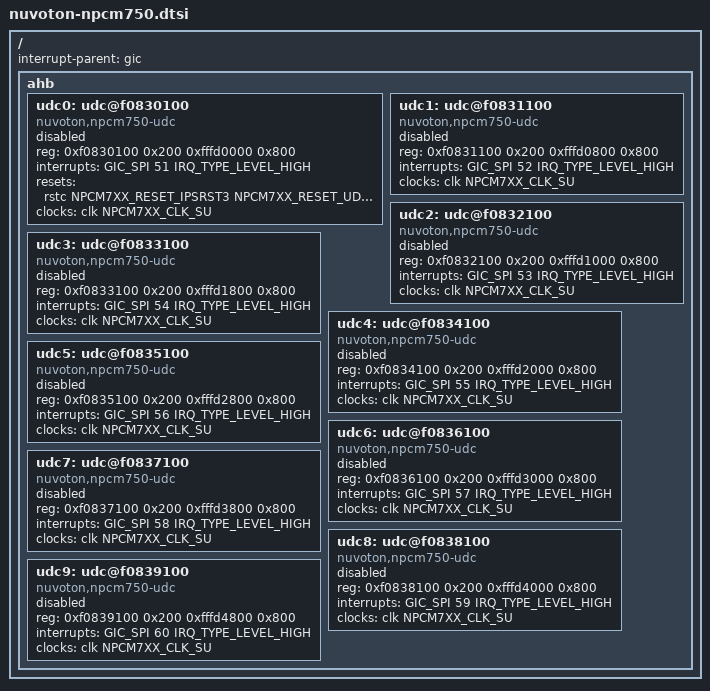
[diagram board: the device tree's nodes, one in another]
// SPDX-License-Identifier: GPL-2.0
// Copyright (c) 2018 Nuvoton Technology tomer.maimon@nuvoton.com
// Copyright 2018 Google, Inc.

#include "nuvoton-common-npcm7xx.dtsi"

/ {
	#address-cells = <1>;
	#size-cells = <1>;
	interrupt-parent = <&gic>;

	ahb {
		udc0:udc@f0830100 {
			compatible = "nuvoton,npcm750-udc";
			reg = <0xf0830100 0x200
			       0xfffd0000 0x800>;
			interrupts = <GIC_SPI 51 IRQ_TYPE_LEVEL_HIGH>;
			resets = <&rstc NPCM7XX_RESET_IPSRST3 NPCM7XX_RESET_UDC0>;
			status = "disabled";
			clocks = <&clk NPCM7XX_CLK_SU>;
			clock-names = "clk_usb_bridge";
		};

		udc1:udc@f0831100 {
			compatible = "nuvoton,npcm750-udc";
			reg = <0xf0831100 0x200
			       0xfffd0800 0x800>;
			interrupts = <GIC_SPI 52 IRQ_TYPE_LEVEL_HIGH>;
			status = "disabled";
			clocks = <&clk NPCM7XX_CLK_SU>;
			clock-names = "clk_usb_bridge";
		};

		udc2: udc@f0832100 {
			compatible = "nuvoton,npcm750-udc";
			reg = <0xf0832100 0x200
			       0xfffd1000 0x800>;
			interrupts = <GIC_SPI 53 IRQ_TYPE_LEVEL_HIGH>;
			status = "disabled";
			clocks = <&clk NPCM7XX_CLK_SU>;
			clock-names = "clk_usb_bridge";
		};

		udc3: udc@f0833100 {
			compatible = "nuvoton,npcm750-udc";
			reg = <0xf0833100 0x200
			       0xfffd1800 0x800>;
			interrupts = <GIC_SPI 54 IRQ_TYPE_LEVEL_HIGH>;
			status = "disabled";
			clocks = <&clk NPCM7XX_CLK_SU>;
			clock-names = "clk_usb_bridge";
		};

		udc4: udc@f0834100 {
			compatible = "nuvoton,npcm750-udc";
			reg = <0xf0834100 0x200
			       0xfffd2000 0x800>;
			interrupts = <GIC_SPI 55 IRQ_TYPE_LEVEL_HIGH>;
			status = "disabled";
			clocks = <&clk NPCM7XX_CLK_SU>;
			clock-names = "clk_usb_bridge";
		};

		udc5: udc@f0835100 {
			compatible = "nuvoton,npcm750-udc";
			reg = <0xf0835100 0x200
			       0xfffd2800 0x800>;
			interrupts = <GIC_SPI 56 IRQ_TYPE_LEVEL_HIGH>;
			status = "disabled";
			clocks = <&clk NPCM7XX_CLK_SU>;
			clock-names = "clk_usb_bridge";
		};

		udc6: udc@f0836100 {
			compatible = "nuvoton,npcm750-udc";
			reg = <0xf0836100 0x200
			       0xfffd3000 0x800>;
			interrupts = <GIC_SPI 57 IRQ_TYPE_LEVEL_HIGH>;
			status = "disabled";
			clocks = <&clk NPCM7XX_CLK_SU>;
			clock-names = "clk_usb_bridge";
		};

		udc7: udc@f0837100 {
			compatible = "nuvoton,npcm750-udc";
			reg = <0xf0837100 0x200
			       0xfffd3800 0x800>;
			interrupts = <GIC_SPI 58 IRQ_TYPE_LEVEL_HIGH>;
			status = "disabled";
			clocks = <&clk NPCM7XX_CLK_SU>;
			clock-names = "clk_usb_bridge";
		};

		udc8: udc@f0838100 {
			compatible = "nuvoton,npcm750-udc";
			reg = <0xf0838100 0x200
			       0xfffd4000 0x800>;
			interrupts = <GIC_SPI 59 IRQ_TYPE_LEVEL_HIGH>;
			status = "disabled";
			clocks = <&clk NPCM7XX_CLK_SU>;
			clock-names = "clk_usb_bridge";
		};

		udc9: udc@f0839100 {
			compatible = "nuvoton,npcm750-udc";
			reg = <0xf0839100 0x200
			       0xfffd4800 0x800>;
			interrupts = <GIC_SPI 60 IRQ_TYPE_LEVEL_HIGH>;
			status = "disabled";
			clocks = <&clk NPCM7XX_CLK_SU>;
			clock-names = "clk_usb_bridge";
		};
	};
};
